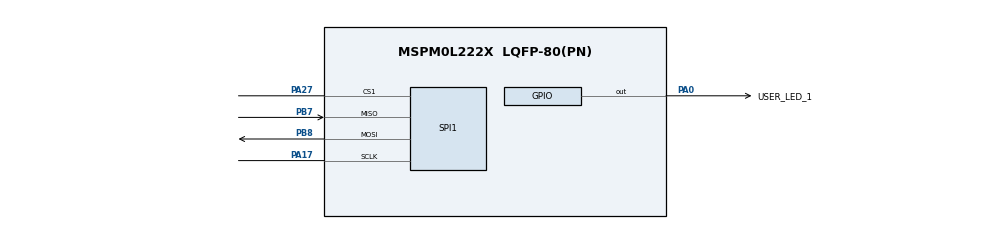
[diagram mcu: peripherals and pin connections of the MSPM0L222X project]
 // @cliArgs --device "MSPM0L222X" --package "LQFP-80(PN)" --part "Default"
// @cliArgs --board /ti/boards/LP_MSPM0L2228 --rtos nortos

 /**
 * Import the modules used in this configuration.
 */
const GPIO  = scripting.addModule("/ti/driverlib/GPIO", {}, false);
const GPIO1 = GPIO.addInstance();
const SPI   = scripting.addModule("/ti/driverlib/SPI", {}, false);
const SPI1  = SPI.addInstance();

/**
 * Write custom configuration values to the imported modules.
 */
GPIO1.$name                         = "GPIO_LEDS";
GPIO1.associatedPins.create(2);
GPIO1.associatedPins[0].$name       = "USER_LED_1";
GPIO1.associatedPins[0].initialValue        = "SET";
GPIO1.associatedPins[0].pin.$assign = "PA0";
GPIO1.associatedPins[1].$name               = "USER_TEST";
GPIO1.associatedPins[1].assignedPort        = "PORTA";
GPIO1.associatedPins[1].assignedPin         = "21";
GPIO1.associatedPins[1].initialValue        = "SET";

const Board = scripting.addModule("/ti/driverlib/Board", {}, false);

SPI1.$name                      = "SPI_0";
SPI1.targetBitRate              = 500000;
SPI1.chipSelect                 = ["1"];
SPI1.rxFifoThreshold            = "DL_SPI_RX_FIFO_LEVEL_ONE_FRAME";
SPI1.peripheral.$assign         = "SPI1";
SPI1.peripheral.sclkPin.$assign = "PA17";
SPI1.peripheral.mosiPin.$assign = "PB8";
SPI1.peripheral.misoPin.$assign = "PB7";
SPI1.peripheral.cs1Pin.$assign  = "PA27";

const SYSCTL = scripting.addModule("/ti/driverlib/SYSCTL", {}, false);
SYSCTL.clockTreeEn = true;
